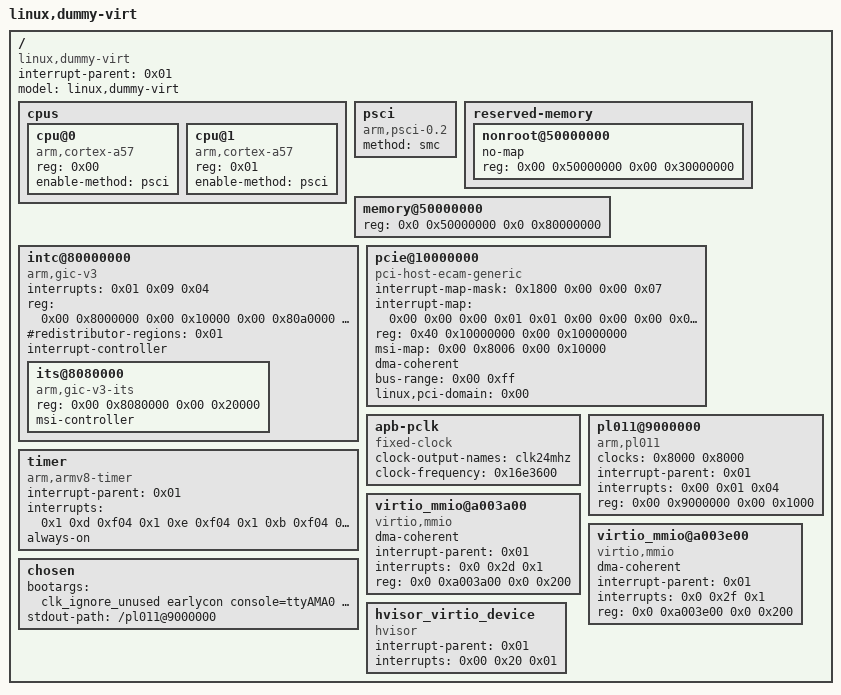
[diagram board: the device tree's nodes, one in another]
/dts-v1/;

/ {
	#size-cells = <0x2>;
	#address-cells = <0x2>;
	interrupt-parent = <0x01>;
	model = "linux,dummy-virt";
	compatible = "linux,dummy-virt";

	cpus {
		#size-cells = <0x00>;
		#address-cells = <0x01>;

		cpu@0 {
			phandle = <0x8010>;
			reg = <0x00>;
			enable-method = "psci";
			compatible = "arm,cortex-a57";
			device_type = "cpu";
		};

		cpu@1 {
			phandle = <0x800f>;
			reg = <0x01>;
			enable-method = "psci";
			compatible = "arm,cortex-a57";
			device_type = "cpu";
		};

	};

	psci {
		compatible = "arm,psci-0.2";
		method = "smc";
	};

	reserved-memory {
		#address-cells = <0x02>;
		#size-cells = <0x02>;
		ranges;

		nonroot@50000000 {
			no-map;
			reg = <0x00 0x50000000 0x00 0x30000000>;
		};
	};

	memory@50000000 {
		device_type = "memory";
		reg = <0x0 0x50000000 0x0 0x80000000>;
	};

	intc@80000000 {
		phandle = <0x01>;
		interrupts = <0x01 0x09 0x04>;
		reg = <0x00 0x8000000 0x00 0x10000 0x00 0x80a0000 0x00 0xf60000>;
		#redistributor-regions = <0x01>;
		compatible = "arm,gic-v3";
		ranges;
		#size-cells = <0x02>;
		#address-cells = <0x02>;
		interrupt-controller;
		#interrupt-cells = <0x03>;

		its@8080000 {
			phandle = <0x8006>;
			reg = <0x00 0x8080000 0x00 0x20000>;
			#msi-cells = <0x01>;
			msi-controller;
			compatible = "arm,gic-v3-its";
		};
	};

	pcie@10000000 {
		interrupt-map-mask = <0x1800 0x00 0x00 0x07>;
		interrupt-map = <0x00 0x00 0x00 0x01 0x01 0x00 0x00 0x00 0x03 0x04 0x00 0x00 0x00 0x02 0x01 0x00 0x00 0x00 0x04 0x04 0x00 0x00 0x00 0x03 0x01 0x00 0x00 0x00 0x05 0x04 0x00 0x00 0x00 0x04 0x01 0x00 0x00 0x00 0x06 0x04 0x800 0x00 0x00 0x01 0x01 0x00 0x00 0x00 0x04 0x04 0x800 0x00 0x00 0x02 0x01 0x00 0x00 0x00 0x05 0x04 0x800 0x00 0x00 0x03 0x01 0x00 0x00 0x00 0x06 0x04 0x800 0x00 0x00 0x04 0x01 0x00 0x00 0x00 0x03 0x04 0x1000 0x00 0x00 0x01 0x01 0x00 0x00 0x00 0x05 0x04 0x1000 0x00 0x00 0x02 0x01 0x00 0x00 0x00 0x06 0x04 0x1000 0x00 0x00 0x03 0x01 0x00 0x00 0x00 0x03 0x04 0x1000 0x00 0x00 0x04 0x01 0x00 0x00 0x00 0x04 0x04 0x1800 0x00 0x00 0x01 0x01 0x00 0x00 0x00 0x06 0x04 0x1800 0x00 0x00 0x02 0x01 0x00 0x00 0x00 0x03 0x04 0x1800 0x00 0x00 0x03 0x01 0x00 0x00 0x00 0x04 0x04 0x1800 0x00 0x00 0x04 0x01 0x00 0x00 0x00 0x05 0x04>;
		#interrupt-cells = <0x01>;
		ranges = <0x1000000 0x00 0x00 0x00 0x3eff0000 0x00 0x10000 
		0x2000000 0x00 0x10000000 0x00 0x10000000 0x00 0x2eff0000 
		0x3000000 0x80 0x00 0x80 0x00 0x80 0x00>;
		reg = <0x40 0x10000000 0x00 0x10000000>;
		msi-map = <0x00 0x8006 0x00 0x10000>;
		dma-coherent;
		bus-range = <0x00 0xff>;
		linux,pci-domain = <0x00>;
		#size-cells = <0x02>;
		#address-cells = <0x03>;
		device_type = "pci";
		compatible = "pci-host-ecam-generic";
	};

	apb-pclk {
		phandle = <0x8000>;
		clock-output-names = "clk24mhz";
		clock-frequency = <0x16e3600>;
		#clock-cells = <0x00>;
		compatible = "fixed-clock";
	};

	pl011@9000000 {
		clock-names = "uartclk\0apb_pclk";
		clocks = <0x8000 0x8000>;
		interrupt-parent = <0x01>;
		interrupts = <0x00 0x01 0x04>;
		reg = <0x00 0x9000000 0x00 0x1000>;
		compatible = "arm,pl011\0arm,primecell";
	};

	timer {
		interrupt-parent = <0x01>;
		interrupts = <0x1 0xd 0xf04 0x1 0xe 0xf04 0x1 0xb 0xf04 0x1 0xa 0xf04>;
		always-on;
		compatible = "arm,armv8-timer", "arm,armv7-timer";
	};

	// virtio_mmio@a003000 {
	// 	dma-coherent;
	//  interrupt-parent = <0x01>;
	// 	interrupts = <0x0 0x28 0x1>;
	// 	reg = <0x0 0xa003000 0x0 0x200>;
	// 	compatible = "virtio,mmio";
	// };

	// virtio_mmio@a003200 {
	// 	dma-coherent;
	//  interrupt-parent = <0x01>;
	// 	interrupts = <0x0 0x29 0x1>;
	// 	reg = <0x0 0xa003200 0x0 0x200>;
	// 	compatible = "virtio,mmio";
	// };


	// virtio_mmio@a003400 {
	// 	dma-coherent;
	//  interrupt-parent = <0x01>;
	// 	interrupts = <0x0 0x2a 0x1>;
	// 	reg = <0x0 0xa003400 0x0 0x200>;
	// 	compatible = "virtio,mmio";
	// };

	// virtio 9p-pci
	// virtio_mmio@a003600 {
	// 	dma-coherent;
	// 	interrupt-parent = <0x01>;
	// 	interrupts = <0x0 0x2b 0x1>;
	// 	reg = <0x0 0xa003600 0x0 0x200>;
	// 	compatible = "virtio,mmio";
	// };

	// virtio serial
	// virtio_mmio@a003800 {
	// 	dma-coherent;
	//  interrupt-parent = <0x01>;
	// 	interrupts = <0x0 0x2c 0x1>;
	// 	reg = <0x0 0xa003800 0x0 0x200>;
	// 	compatible = "virtio,mmio";
	// };

	// virtio net
	virtio_mmio@a003a00 {
		dma-coherent;
		interrupt-parent = <0x01>;
		interrupts = <0x0 0x2d 0x1>;
		reg = <0x0 0xa003a00 0x0 0x200>;
		compatible = "virtio,mmio";
	};

	// virtio disk-second
	// virtio_mmio@a003c00 {
	// 	dma-coherent;
	//  interrupt-parent = <0x01>;
	// 	interrupts = <0x0 0x2e 0x1>;
	// 	reg = <0x0 0xa003c00 0x0 0x200>;
	// 	compatible = "virtio,mmio";
	// };

	// virtio disk-first
	virtio_mmio@a003e00 {
		dma-coherent;
		interrupt-parent = <0x01>;
		interrupts = <0x0 0x2f 0x1>;
		reg = <0x0 0xa003e00 0x0 0x200>;
		compatible = "virtio,mmio";
	};

	chosen {
		bootargs = "clk_ignore_unused earlycon console=ttyAMA0 root=/dev/vda iomem=relaxed rw";
        // bootargs = "root=/dev/vda mem=768M";
		stdout-path = "/pl011@9000000";
	};

	hvisor_virtio_device {
		compatible = "hvisor";
		interrupt-parent = <0x01>;
		interrupts = <0x00 0x20 0x01>;
	};
};
